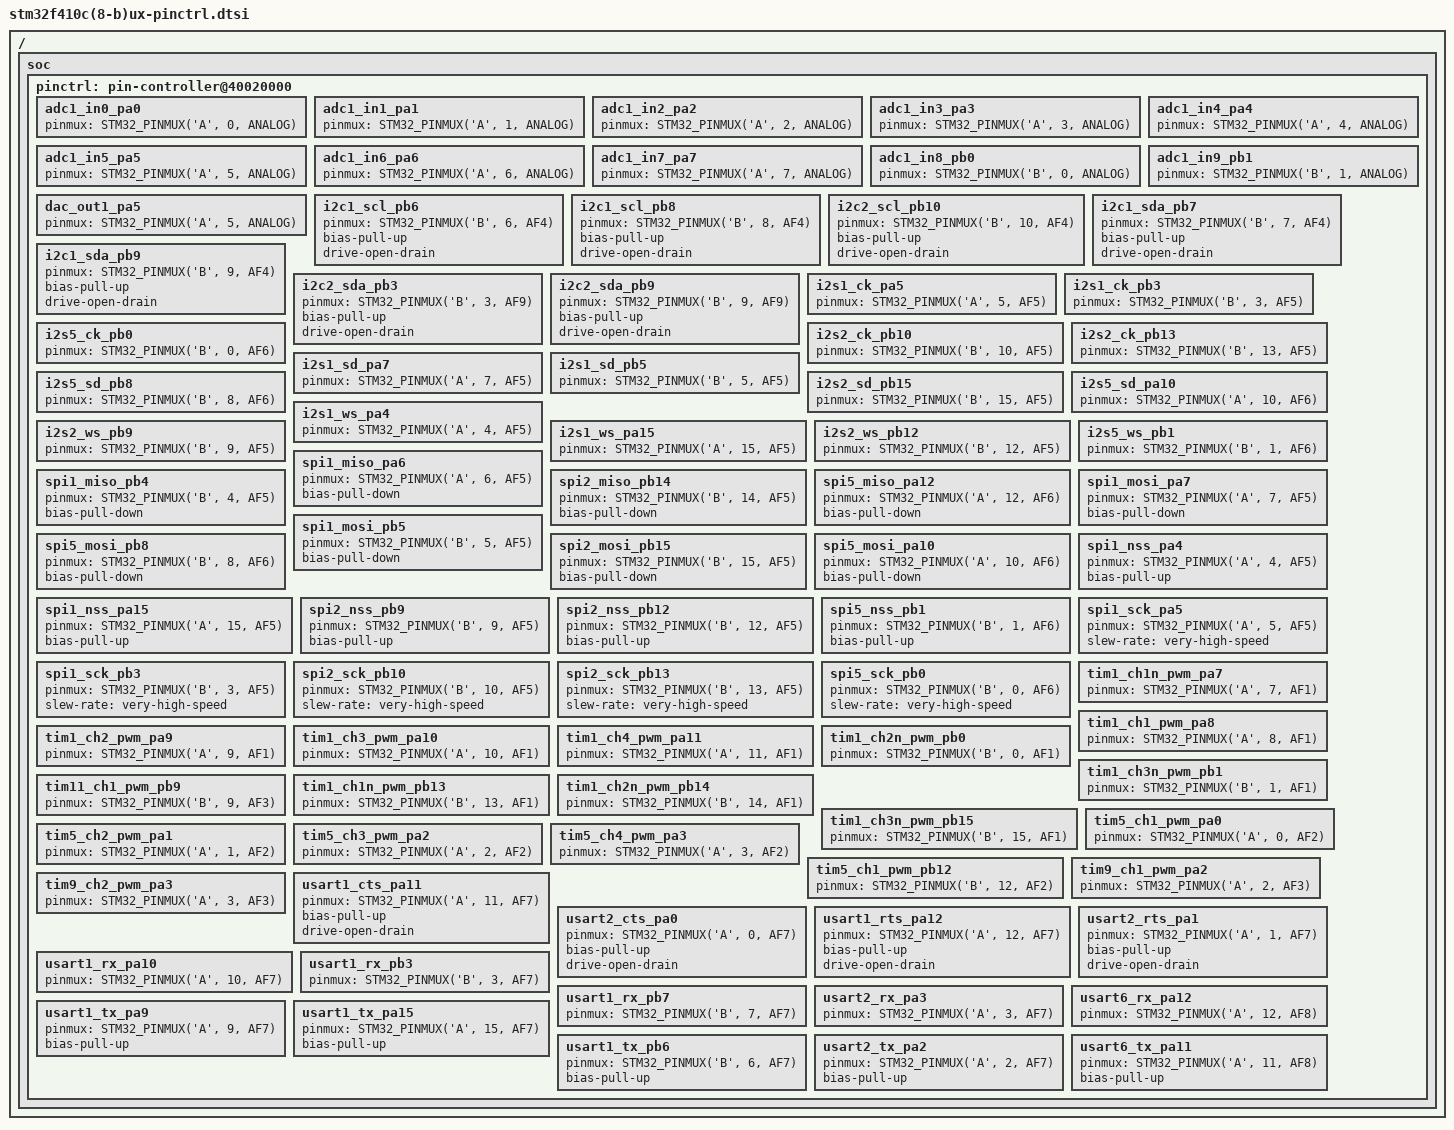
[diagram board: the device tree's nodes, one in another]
/*
 * NOTE: Autogenerated file using genpinctrl.py
 *
 * SPDX-License-Identifier: Apache-2.0
 */

#include <dt-bindings/pinctrl/stm32-pinctrl.h>

/ {
	soc {
		pinctrl: pin-controller@40020000 {

			/* ADC_IN / ADC_INN / ADC_INP */

			adc1_in0_pa0: adc1_in0_pa0 {
				pinmux = <STM32_PINMUX('A', 0, ANALOG)>;
			};

			adc1_in1_pa1: adc1_in1_pa1 {
				pinmux = <STM32_PINMUX('A', 1, ANALOG)>;
			};

			adc1_in2_pa2: adc1_in2_pa2 {
				pinmux = <STM32_PINMUX('A', 2, ANALOG)>;
			};

			adc1_in3_pa3: adc1_in3_pa3 {
				pinmux = <STM32_PINMUX('A', 3, ANALOG)>;
			};

			adc1_in4_pa4: adc1_in4_pa4 {
				pinmux = <STM32_PINMUX('A', 4, ANALOG)>;
			};

			adc1_in5_pa5: adc1_in5_pa5 {
				pinmux = <STM32_PINMUX('A', 5, ANALOG)>;
			};

			adc1_in6_pa6: adc1_in6_pa6 {
				pinmux = <STM32_PINMUX('A', 6, ANALOG)>;
			};

			adc1_in7_pa7: adc1_in7_pa7 {
				pinmux = <STM32_PINMUX('A', 7, ANALOG)>;
			};

			adc1_in8_pb0: adc1_in8_pb0 {
				pinmux = <STM32_PINMUX('B', 0, ANALOG)>;
			};

			adc1_in9_pb1: adc1_in9_pb1 {
				pinmux = <STM32_PINMUX('B', 1, ANALOG)>;
			};

			/* DAC_OUT */

			dac_out1_pa5: dac_out1_pa5 {
				pinmux = <STM32_PINMUX('A', 5, ANALOG)>;
			};

			/* I2C_SCL */

			i2c1_scl_pb6: i2c1_scl_pb6 {
				pinmux = <STM32_PINMUX('B', 6, AF4)>;
				bias-pull-up;
				drive-open-drain;
			};

			i2c1_scl_pb8: i2c1_scl_pb8 {
				pinmux = <STM32_PINMUX('B', 8, AF4)>;
				bias-pull-up;
				drive-open-drain;
			};

			i2c2_scl_pb10: i2c2_scl_pb10 {
				pinmux = <STM32_PINMUX('B', 10, AF4)>;
				bias-pull-up;
				drive-open-drain;
			};

			/* I2C_SDA */

			i2c1_sda_pb7: i2c1_sda_pb7 {
				pinmux = <STM32_PINMUX('B', 7, AF4)>;
				bias-pull-up;
				drive-open-drain;
			};

			i2c1_sda_pb9: i2c1_sda_pb9 {
				pinmux = <STM32_PINMUX('B', 9, AF4)>;
				bias-pull-up;
				drive-open-drain;
			};

			i2c2_sda_pb3: i2c2_sda_pb3 {
				pinmux = <STM32_PINMUX('B', 3, AF9)>;
				bias-pull-up;
				drive-open-drain;
			};

			i2c2_sda_pb9: i2c2_sda_pb9 {
				pinmux = <STM32_PINMUX('B', 9, AF9)>;
				bias-pull-up;
				drive-open-drain;
			};

			/* I2S_CK */

			i2s1_ck_pa5: i2s1_ck_pa5 {
				pinmux = <STM32_PINMUX('A', 5, AF5)>;
			};

			i2s1_ck_pb3: i2s1_ck_pb3 {
				pinmux = <STM32_PINMUX('B', 3, AF5)>;
			};

			i2s2_ck_pb10: i2s2_ck_pb10 {
				pinmux = <STM32_PINMUX('B', 10, AF5)>;
			};

			i2s2_ck_pb13: i2s2_ck_pb13 {
				pinmux = <STM32_PINMUX('B', 13, AF5)>;
			};

			i2s5_ck_pb0: i2s5_ck_pb0 {
				pinmux = <STM32_PINMUX('B', 0, AF6)>;
			};

			/* I2S_SD */

			i2s1_sd_pa7: i2s1_sd_pa7 {
				pinmux = <STM32_PINMUX('A', 7, AF5)>;
			};

			i2s1_sd_pb5: i2s1_sd_pb5 {
				pinmux = <STM32_PINMUX('B', 5, AF5)>;
			};

			i2s2_sd_pb15: i2s2_sd_pb15 {
				pinmux = <STM32_PINMUX('B', 15, AF5)>;
			};

			i2s5_sd_pa10: i2s5_sd_pa10 {
				pinmux = <STM32_PINMUX('A', 10, AF6)>;
			};

			i2s5_sd_pb8: i2s5_sd_pb8 {
				pinmux = <STM32_PINMUX('B', 8, AF6)>;
			};

			/* I2S_WS */

			i2s1_ws_pa4: i2s1_ws_pa4 {
				pinmux = <STM32_PINMUX('A', 4, AF5)>;
			};

			i2s1_ws_pa15: i2s1_ws_pa15 {
				pinmux = <STM32_PINMUX('A', 15, AF5)>;
			};

			i2s2_ws_pb9: i2s2_ws_pb9 {
				pinmux = <STM32_PINMUX('B', 9, AF5)>;
			};

			i2s2_ws_pb12: i2s2_ws_pb12 {
				pinmux = <STM32_PINMUX('B', 12, AF5)>;
			};

			i2s5_ws_pb1: i2s5_ws_pb1 {
				pinmux = <STM32_PINMUX('B', 1, AF6)>;
			};

			/* SPI_MISO */

			spi1_miso_pa6: spi1_miso_pa6 {
				pinmux = <STM32_PINMUX('A', 6, AF5)>;
				bias-pull-down;
			};

			spi1_miso_pb4: spi1_miso_pb4 {
				pinmux = <STM32_PINMUX('B', 4, AF5)>;
				bias-pull-down;
			};

			spi2_miso_pb14: spi2_miso_pb14 {
				pinmux = <STM32_PINMUX('B', 14, AF5)>;
				bias-pull-down;
			};

			spi5_miso_pa12: spi5_miso_pa12 {
				pinmux = <STM32_PINMUX('A', 12, AF6)>;
				bias-pull-down;
			};

			/* SPI_MOSI */

			spi1_mosi_pa7: spi1_mosi_pa7 {
				pinmux = <STM32_PINMUX('A', 7, AF5)>;
				bias-pull-down;
			};

			spi1_mosi_pb5: spi1_mosi_pb5 {
				pinmux = <STM32_PINMUX('B', 5, AF5)>;
				bias-pull-down;
			};

			spi2_mosi_pb15: spi2_mosi_pb15 {
				pinmux = <STM32_PINMUX('B', 15, AF5)>;
				bias-pull-down;
			};

			spi5_mosi_pa10: spi5_mosi_pa10 {
				pinmux = <STM32_PINMUX('A', 10, AF6)>;
				bias-pull-down;
			};

			spi5_mosi_pb8: spi5_mosi_pb8 {
				pinmux = <STM32_PINMUX('B', 8, AF6)>;
				bias-pull-down;
			};

			/* SPI_NSS */

			spi1_nss_pa4: spi1_nss_pa4 {
				pinmux = <STM32_PINMUX('A', 4, AF5)>;
				bias-pull-up;
			};

			spi1_nss_pa15: spi1_nss_pa15 {
				pinmux = <STM32_PINMUX('A', 15, AF5)>;
				bias-pull-up;
			};

			spi2_nss_pb9: spi2_nss_pb9 {
				pinmux = <STM32_PINMUX('B', 9, AF5)>;
				bias-pull-up;
			};

			spi2_nss_pb12: spi2_nss_pb12 {
				pinmux = <STM32_PINMUX('B', 12, AF5)>;
				bias-pull-up;
			};

			spi5_nss_pb1: spi5_nss_pb1 {
				pinmux = <STM32_PINMUX('B', 1, AF6)>;
				bias-pull-up;
			};

			/* SPI_SCK */

			spi1_sck_pa5: spi1_sck_pa5 {
				pinmux = <STM32_PINMUX('A', 5, AF5)>;
				slew-rate = "very-high-speed";
			};

			spi1_sck_pb3: spi1_sck_pb3 {
				pinmux = <STM32_PINMUX('B', 3, AF5)>;
				slew-rate = "very-high-speed";
			};

			spi2_sck_pb10: spi2_sck_pb10 {
				pinmux = <STM32_PINMUX('B', 10, AF5)>;
				slew-rate = "very-high-speed";
			};

			spi2_sck_pb13: spi2_sck_pb13 {
				pinmux = <STM32_PINMUX('B', 13, AF5)>;
				slew-rate = "very-high-speed";
			};

			spi5_sck_pb0: spi5_sck_pb0 {
				pinmux = <STM32_PINMUX('B', 0, AF6)>;
				slew-rate = "very-high-speed";
			};

			/* TIM_CH_PWM / TIM_CHN_PWM */

			tim1_ch1n_pwm_pa7: tim1_ch1n_pwm_pa7 {
				pinmux = <STM32_PINMUX('A', 7, AF1)>;
			};

			tim1_ch1_pwm_pa8: tim1_ch1_pwm_pa8 {
				pinmux = <STM32_PINMUX('A', 8, AF1)>;
			};

			tim1_ch2_pwm_pa9: tim1_ch2_pwm_pa9 {
				pinmux = <STM32_PINMUX('A', 9, AF1)>;
			};

			tim1_ch3_pwm_pa10: tim1_ch3_pwm_pa10 {
				pinmux = <STM32_PINMUX('A', 10, AF1)>;
			};

			tim1_ch4_pwm_pa11: tim1_ch4_pwm_pa11 {
				pinmux = <STM32_PINMUX('A', 11, AF1)>;
			};

			tim1_ch2n_pwm_pb0: tim1_ch2n_pwm_pb0 {
				pinmux = <STM32_PINMUX('B', 0, AF1)>;
			};

			tim1_ch3n_pwm_pb1: tim1_ch3n_pwm_pb1 {
				pinmux = <STM32_PINMUX('B', 1, AF1)>;
			};

			tim11_ch1_pwm_pb9: tim11_ch1_pwm_pb9 {
				pinmux = <STM32_PINMUX('B', 9, AF3)>;
			};

			tim1_ch1n_pwm_pb13: tim1_ch1n_pwm_pb13 {
				pinmux = <STM32_PINMUX('B', 13, AF1)>;
			};

			tim1_ch2n_pwm_pb14: tim1_ch2n_pwm_pb14 {
				pinmux = <STM32_PINMUX('B', 14, AF1)>;
			};

			tim1_ch3n_pwm_pb15: tim1_ch3n_pwm_pb15 {
				pinmux = <STM32_PINMUX('B', 15, AF1)>;
			};

			tim5_ch1_pwm_pa0: tim5_ch1_pwm_pa0 {
				pinmux = <STM32_PINMUX('A', 0, AF2)>;
			};

			tim5_ch2_pwm_pa1: tim5_ch2_pwm_pa1 {
				pinmux = <STM32_PINMUX('A', 1, AF2)>;
			};

			tim5_ch3_pwm_pa2: tim5_ch3_pwm_pa2 {
				pinmux = <STM32_PINMUX('A', 2, AF2)>;
			};

			tim5_ch4_pwm_pa3: tim5_ch4_pwm_pa3 {
				pinmux = <STM32_PINMUX('A', 3, AF2)>;
			};

			tim5_ch1_pwm_pb12: tim5_ch1_pwm_pb12 {
				pinmux = <STM32_PINMUX('B', 12, AF2)>;
			};

			tim9_ch1_pwm_pa2: tim9_ch1_pwm_pa2 {
				pinmux = <STM32_PINMUX('A', 2, AF3)>;
			};

			tim9_ch2_pwm_pa3: tim9_ch2_pwm_pa3 {
				pinmux = <STM32_PINMUX('A', 3, AF3)>;
			};

			/* UART_CTS / USART_CTS / LPUART_CTS */

			usart1_cts_pa11: usart1_cts_pa11 {
				pinmux = <STM32_PINMUX('A', 11, AF7)>;
				bias-pull-up;
				drive-open-drain;
			};

			usart2_cts_pa0: usart2_cts_pa0 {
				pinmux = <STM32_PINMUX('A', 0, AF7)>;
				bias-pull-up;
				drive-open-drain;
			};

			/* UART_RTS / USART_RTS / LPUART_RTS */

			usart1_rts_pa12: usart1_rts_pa12 {
				pinmux = <STM32_PINMUX('A', 12, AF7)>;
				bias-pull-up;
				drive-open-drain;
			};

			usart2_rts_pa1: usart2_rts_pa1 {
				pinmux = <STM32_PINMUX('A', 1, AF7)>;
				bias-pull-up;
				drive-open-drain;
			};

			/* UART_RX / USART_RX / LPUART_RX */

			usart1_rx_pa10: usart1_rx_pa10 {
				pinmux = <STM32_PINMUX('A', 10, AF7)>;
			};

			usart1_rx_pb3: usart1_rx_pb3 {
				pinmux = <STM32_PINMUX('B', 3, AF7)>;
			};

			usart1_rx_pb7: usart1_rx_pb7 {
				pinmux = <STM32_PINMUX('B', 7, AF7)>;
			};

			usart2_rx_pa3: usart2_rx_pa3 {
				pinmux = <STM32_PINMUX('A', 3, AF7)>;
			};

			usart6_rx_pa12: usart6_rx_pa12 {
				pinmux = <STM32_PINMUX('A', 12, AF8)>;
			};

			/* UART_TX / USART_TX / LPUART_TX */

			usart1_tx_pa9: usart1_tx_pa9 {
				pinmux = <STM32_PINMUX('A', 9, AF7)>;
				bias-pull-up;
			};

			usart1_tx_pa15: usart1_tx_pa15 {
				pinmux = <STM32_PINMUX('A', 15, AF7)>;
				bias-pull-up;
			};

			usart1_tx_pb6: usart1_tx_pb6 {
				pinmux = <STM32_PINMUX('B', 6, AF7)>;
				bias-pull-up;
			};

			usart2_tx_pa2: usart2_tx_pa2 {
				pinmux = <STM32_PINMUX('A', 2, AF7)>;
				bias-pull-up;
			};

			usart6_tx_pa11: usart6_tx_pa11 {
				pinmux = <STM32_PINMUX('A', 11, AF8)>;
				bias-pull-up;
			};

		};
	};
};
